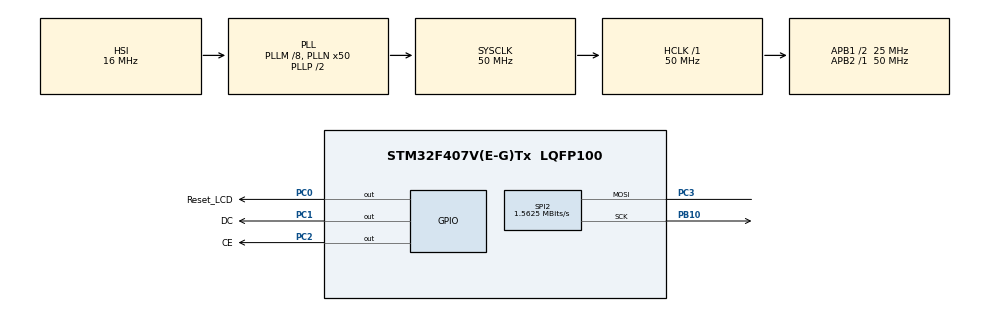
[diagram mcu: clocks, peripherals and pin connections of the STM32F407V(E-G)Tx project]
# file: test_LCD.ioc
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Mcu.Family=STM32F4
Mcu.Name=STM32F407V(E-G)Tx
Mcu.Package=LQFP100
NVIC.PriorityGroup=NVIC_PRIORITYGROUP_4
PB10.Mode=Simplex_Bidirectional_Master
PB10.Signal=SPI2_SCK
PC0.GPIO_Label=Reset_LCD
PC0.Signal=GPIO_Output
PC1.GPIO_Label=DC
PC1.Signal=GPIO_Output
PC2.GPIO_Label=CE
PC2.Signal=GPIO_Output
PC3.Mode=Simplex_Bidirectional_Master
PC3.Signal=SPI2_MOSI
ProjectManager.HeapSize=0x200
ProjectManager.StackSize=0x400
ProjectManager.TargetToolchain=Makefile
RCC.48MHZClocksFreq_Value=25000000
RCC.AHBFreq_Value=50000000
RCC.APB1CLKDivider=RCC_HCLK_DIV2
RCC.APB1Freq_Value=25000000
RCC.APB1TimFreq_Value=50000000
RCC.APB2Freq_Value=50000000
RCC.APB2TimFreq_Value=50000000
RCC.CortexFreq_Value=50000000
RCC.HCLKFreq_Value=50000000
RCC.HSE_VALUE=25000000
RCC.HSI_VALUE=16000000
RCC.LSE_VALUE=32768
RCC.PLLM=8
RCC.PLLN=50
RCC.SYSCLKFreq_VALUE=50000000
RCC.SYSCLKSource=RCC_SYSCLKSOURCE_PLLCLK
RCC.VCOOutputFreq_Value=100000000
SPI2.BaudRatePrescaler=SPI_BAUDRATEPRESCALER_16
SPI2.CalculateBaudRate=1.5625 MBits/s
SPI2.Direction=SPI_DIRECTION_1LINE
SPI2.Mode=SPI_MODE_MASTER
SPI2.VirtualType=VM_MASTER
board=custom

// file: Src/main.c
/* USER CODE BEGIN Header */
/**
  ******************************************************************************
  * @file           : main.c
  * @brief          : Main program body
  ******************************************************************************
  * @attention
  *
  * <h2><center>&copy; Copyright (c) 2020 STMicroelectronics.
  * All rights reserved.</center></h2>
  *
  * This software component is licensed by ST under BSD 3-Clause license,
  * the "License"; You may not use this file except in compliance with the
  * License. You may obtain a copy of the License at:
  *                        opensource.org/licenses/BSD-3-Clause
  *
  ******************************************************************************
  */
/* USER CODE END Header */

#include "main.h"

/* USER CODE BEGIN Includes */
#include "LCD5510.h"
#include "Graphichs.h"
/* USER CODE END Includes */

SPI_HandleTypeDef hspi2;

void SystemClock_Config(void);
static void MX_GPIO_Init(void);
static void MX_SPI2_Init(void);

int main(void)
{

  /* MCU Configuration--------------------------------------------------------*/

  /* Reset of all peripherals, Initializes the Flash interface and the Systick. */
  HAL_Init();

  /* Configure the system clock */
  SystemClock_Config();

  /* Initialize all configured peripherals */
  MX_GPIO_Init();
  MX_SPI2_Init();
  /* USER CODE BEGIN 2 */
  LCD_Init();

  drawRectangle(5,0,80,5);
  LCD_Write_String(15,1,"Ali ihsan");
  LCD_Write_String(18,2,"Cengiz");
  makeInverseVideoMode();
  HAL_Delay(1000);
  makeNormalVideoMode();
  HAL_Delay(1000);
  makeInverseVideoMode();
  HAL_Delay(1000);
  makeNormalVideoMode();

  /* USER CODE END 2 */

  /* Infinite loop */
  while (1)
  {

  }
}

void SystemClock_Config(void)
{
  RCC_OscInitTypeDef RCC_OscInitStruct = {0};
  RCC_ClkInitTypeDef RCC_ClkInitStruct = {0};

  /** Configure the main internal regulator output voltage
  */
  __HAL_RCC_PWR_CLK_ENABLE();
  __HAL_PWR_VOLTAGESCALING_CONFIG(PWR_REGULATOR_VOLTAGE_SCALE1);
  /** Initializes the CPU, AHB and APB busses clocks
  */
  RCC_OscInitStruct.OscillatorType = RCC_OSCILLATORTYPE_HSI;
  RCC_OscInitStruct.HSIState = RCC_HSI_ON;
  RCC_OscInitStruct.HSICalibrationValue = RCC_HSICALIBRATION_DEFAULT;
  RCC_OscInitStruct.PLL.PLLState = RCC_PLL_ON;
  RCC_OscInitStruct.PLL.PLLSource = RCC_PLLSOURCE_HSI;
  RCC_OscInitStruct.PLL.PLLM = 8;
  RCC_OscInitStruct.PLL.PLLN = 50;
  RCC_OscInitStruct.PLL.PLLP = RCC_PLLP_DIV2;
  RCC_OscInitStruct.PLL.PLLQ = 4;
  if (HAL_RCC_OscConfig(&RCC_OscInitStruct) != HAL_OK)
  {
    Error_Handler();
  }
  /** Initializes the CPU, AHB and APB busses clocks
  */
  RCC_ClkInitStruct.ClockType = RCC_CLOCKTYPE_HCLK|RCC_CLOCKTYPE_SYSCLK
                              |RCC_CLOCKTYPE_PCLK1|RCC_CLOCKTYPE_PCLK2;
  RCC_ClkInitStruct.SYSCLKSource = RCC_SYSCLKSOURCE_PLLCLK;
  RCC_ClkInitStruct.AHBCLKDivider = RCC_SYSCLK_DIV1;
  RCC_ClkInitStruct.APB1CLKDivider = RCC_HCLK_DIV2;
  RCC_ClkInitStruct.APB2CLKDivider = RCC_HCLK_DIV1;

  if (HAL_RCC_ClockConfig(&RCC_ClkInitStruct, FLASH_LATENCY_1) != HAL_OK)
  {
    Error_Handler();
  }
}

static void MX_SPI2_Init(void)
{

  /* SPI2 parameter configuration*/
  hspi2.Instance = SPI2;
  hspi2.Init.Mode = SPI_MODE_MASTER;
  hspi2.Init.Direction = SPI_DIRECTION_1LINE;
  hspi2.Init.DataSize = SPI_DATASIZE_8BIT;
  hspi2.Init.CLKPolarity = SPI_POLARITY_LOW;
  hspi2.Init.CLKPhase = SPI_PHASE_1EDGE;
  hspi2.Init.NSS = SPI_NSS_SOFT;
  hspi2.Init.BaudRatePrescaler = SPI_BAUDRATEPRESCALER_16;
  hspi2.Init.FirstBit = SPI_FIRSTBIT_MSB;
  hspi2.Init.TIMode = SPI_TIMODE_DISABLE;
  hspi2.Init.CRCCalculation = SPI_CRCCALCULATION_DISABLE;
  hspi2.Init.CRCPolynomial = 10;
  if (HAL_SPI_Init(&hspi2) != HAL_OK)
  {
    Error_Handler();
  }

}

static void MX_GPIO_Init(void)
{
  GPIO_InitTypeDef GPIO_InitStruct = {0};

  /* GPIO Ports Clock Enable */
  __HAL_RCC_GPIOC_CLK_ENABLE();
  __HAL_RCC_GPIOB_CLK_ENABLE();

  /*Configure GPIO pin Output Level */
  HAL_GPIO_WritePin(GPIOC, Reset_LCD_Pin|DC_Pin|CE_Pin, GPIO_PIN_RESET);

  /*Configure GPIO pins : Reset_LCD_Pin DC_Pin CE_Pin */
  GPIO_InitStruct.Pin = Reset_LCD_Pin|DC_Pin|CE_Pin;
  GPIO_InitStruct.Mode = GPIO_MODE_OUTPUT_PP;
  GPIO_InitStruct.Pull = GPIO_NOPULL;
  GPIO_InitStruct.Speed = GPIO_SPEED_FREQ_LOW;
  HAL_GPIO_Init(GPIOC, &GPIO_InitStruct);

}

void Error_Handler(void)
{
}

/************************ (C) COPYRIGHT STMicroelectronics *****END OF FILE****/
